AUTOSAR XML (schema 3.1.2)
package /Components/SWC_AdvOptmT
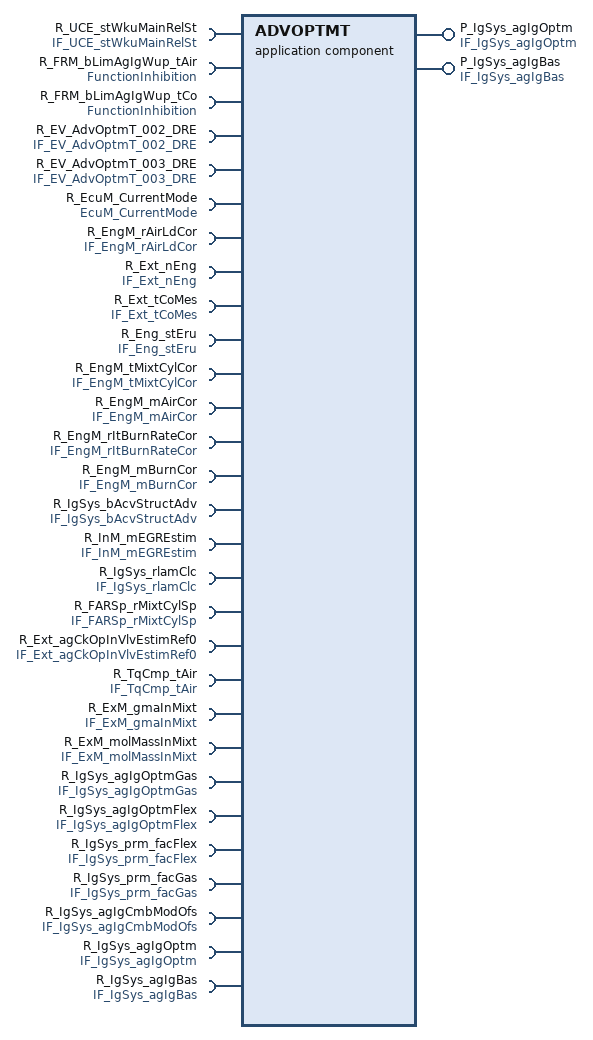
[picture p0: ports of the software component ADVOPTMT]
  application software component type ADVOPTMT  # AdvOptmT
    require port R_UCE_stWkuMainRelSt: required-interface=IF_UCE_stWkuMainRelSt
    require port R_FRM_bLimAgIgWup_tAir: required-interface=FunctionInhibition
    require port R_FRM_bLimAgIgWup_tCo: required-interface=FunctionInhibition
    provide port P_IgSys_agIgOptm: unqueued-sender-com-spec{data-element=IgSys_agIgOptm, can-invalidate=false, init-value=ConstantValue}, provided-interface=IF_IgSys_agIgOptm
    provide port P_IgSys_agIgBas: unqueued-sender-com-spec{data-element=IgSys_agIgBas, can-invalidate=false, init-value=UInt8InitValue}, provided-interface=IF_IgSys_agIgBas
    26 x require port:
      R_EV_AdvOptmT_002_DRE: unqueued-receiver-com-spec{data-element=EV_AdvOptmT_002_DRE, init-value=UInt8InitValue1, resync-time=0}, required-interface=IF_EV_AdvOptmT_002_DRE
      R_EV_AdvOptmT_003_DRE: unqueued-receiver-com-spec{data-element=EV_AdvOptmT_003_DRE, init-value=UInt8InitValue3, resync-time=0}, required-interface=IF_EV_AdvOptmT_003_DRE
      R_EcuM_CurrentMode: required-interface=EcuM_CurrentMode
      R_EngM_rAirLdCor: unqueued-receiver-com-spec{data-element=EngM_rAirLdCor, init-value=ConstantValue5, resync-time=0}, required-interface=IF_EngM_rAirLdCor
      R_Ext_nEng: unqueued-receiver-com-spec{data-element=Ext_nEng, init-value=ConstantValue7, resync-time=0}, required-interface=IF_Ext_nEng
      R_Ext_tCoMes: unqueued-receiver-com-spec{data-element=Ext_tCoMes, init-value=ConstantValue9, resync-time=0}, required-interface=IF_Ext_tCoMes
      R_Eng_stEru: unqueued-receiver-com-spec{data-element=Eng_stEru, init-value=ConstantValue11, resync-time=0}, required-interface=IF_Eng_stEru
      R_EngM_tMixtCylCor: unqueued-receiver-com-spec{data-element=EngM_tMixtCylCor, init-value=UInt16InitValue, resync-time=0}, required-interface=IF_EngM_tMixtCylCor
      R_EngM_mAirCor: unqueued-receiver-com-spec{data-element=EngM_mAirCor, init-value=UInt16InitValue13, resync-time=0}, required-interface=IF_EngM_mAirCor
      R_EngM_rItBurnRateCor: unqueued-receiver-com-spec{data-element=EngM_rItBurnRateCor, init-value=UInt16InitValue15, resync-time=0}, required-interface=IF_EngM_rItBurnRateCor
      R_EngM_mBurnCor: unqueued-receiver-com-spec{data-element=EngM_mBurnCor, init-value=UInt16InitValue17, resync-time=0}, required-interface=IF_EngM_mBurnCor
      R_IgSys_bAcvStructAdv: unqueued-receiver-com-spec{data-element=IgSys_bAcvStructAdv, init-value=ConstantValue19, resync-time=0}, required-interface=IF_IgSys_bAcvStructAdv
      R_InM_mEGREstim: unqueued-receiver-com-spec{data-element=InM_mEGREstim, init-value=UInt32InitValue, resync-time=0}, required-interface=IF_InM_mEGREstim
      R_IgSys_rlamClc: unqueued-receiver-com-spec{data-element=IgSys_rlamClc, init-value=UInt16InitValue21, resync-time=0}, required-interface=IF_IgSys_rlamClc
      R_FARSp_rMixtCylSp: unqueued-receiver-com-spec{data-element=FARSp_rMixtCylSp, init-value=ConstantValue23, resync-time=0}, required-interface=IF_FARSp_rMixtCylSp
      R_Ext_agCkOpInVlvEstimRef0: unqueued-receiver-com-spec{data-element=Ext_agCkOpInVlvEstimRef0, init-value=ConstantValue25, resync-time=0}, required-interface=IF_Ext_agCkOpInVlvEstimRef0
      R_TqCmp_tAir: unqueued-receiver-com-spec{data-element=TqCmp_tAir, init-value=SInt8InitValue, resync-time=0}, required-interface=IF_TqCmp_tAir
      R_ExM_gmaInMixt: unqueued-receiver-com-spec{data-element=ExM_gmaInMixt, init-value=UInt16InitValue27, resync-time=0}, required-interface=IF_ExM_gmaInMixt
      R_ExM_molMassInMixt: unqueued-receiver-com-spec{data-element=ExM_molMassInMixt, init-value=UInt16InitValue29, resync-time=0}, required-interface=IF_ExM_molMassInMixt
      R_IgSys_agIgOptmGas: unqueued-receiver-com-spec{data-element=IgSys_agIgOptmGas, init-value=UInt8InitValue31, resync-time=0}, required-interface=IF_IgSys_agIgOptmGas
      R_IgSys_agIgOptmFlex: unqueued-receiver-com-spec{data-element=IgSys_agIgOptmFlex, init-value=UInt8InitValue33, resync-time=0}, required-interface=IF_IgSys_agIgOptmFlex
      R_IgSys_prm_facFlex: unqueued-receiver-com-spec{data-element=IgSys_prm_facFlex, init-value=ArrayConstantValue, resync-time=0}, required-interface=IF_IgSys_prm_facFlex
      R_IgSys_prm_facGas: unqueued-receiver-com-spec{data-element=IgSys_prm_facGas, init-value=ArrayConstantValue35, resync-time=0}, required-interface=IF_IgSys_prm_facGas
      R_IgSys_agIgCmbModOfs: unqueued-receiver-com-spec{data-element=IgSys_agIgCmbModOfs, init-value=UInt8InitValue37, resync-time=0}, required-interface=IF_IgSys_agIgCmbModOfs
      R_IgSys_agIgOptm: unqueued-receiver-com-spec{data-element=IgSys_agIgOptm, init-value=ConstantValue, resync-time=0}, required-interface=IF_IgSys_agIgOptm
      R_IgSys_agIgBas: unqueued-receiver-com-spec{data-element=IgSys_agIgBas, init-value=UInt8InitValue, resync-time=0}, required-interface=IF_IgSys_agIgBas
  27 x constant specification:
    ArrayConstantValue
      value:
        array specification ArrayConstantValue: type=rt_Array_UInt8_10_m0
          10 x integer literal, all with type=DT_IgSys_prm_facFlex, value=0:
            Const
            Const{1..9}
    ArrayConstantValue35
      value:
        array specification ArrayConstantValue35: type=rt_Array_UInt8_10_m1
          10 x integer literal, all with type=DT_IgSys_prm_facGas, value=0:
            Const
            Const{1..9}
    ConstantValue
      value:
        integer literal ConstantValue: type=DT_IgSys_agIgOptm, value=149
    ConstantValue11
      value:
        integer literal ConstantValue11: type=DT_Eng_stEru, value=1
    ConstantValue19
      value:
        boolean literal ConstantValue19: type=DT_IgSys_bAcvStructAdv, value=false
    ConstantValue23
      value:
        integer literal ConstantValue23: type=DT_FARSp_rMixtCylSp, value=4096
    ConstantValue25
      value:
        integer literal ConstantValue25: type=DT_Ext_agCkOpInVlvEstimRef0, value=-1024
    ConstantValue5
      value:
        integer literal ConstantValue5: type=DT_EngM_rAirLdCor, value=0
    ConstantValue7
      value:
        integer literal ConstantValue7: type=DT_Ext_nEng, value=0
    ConstantValue9
      value:
        integer literal ConstantValue9: type=DT_Ext_tCoMes, value=20
    InitValue_Boolean_0
      value:
        boolean literal InitValue_Boolean_0: type=DT_IgSys_bAcvClsLoop_irv, value=false
    InitValue_Float32_0
      value:
        real literal InitValue_Float32_0: type=DT_IgSys_agIgWup_irv, value=0
    SInt8InitValue
      value:
        integer literal SInt8InitValue: type=DT_TqCmp_tAir, value=-40
    UInt16InitValue
      value:
        integer literal UInt16InitValue: type=DT_EngM_tMixtCylCor, value=0
    UInt16InitValue13
      value:
        integer literal UInt16InitValue13: type=DT_EngM_mAirCor, value=0
    UInt16InitValue15
      value:
        integer literal UInt16InitValue15: type=DT_EngM_rItBurnRateCor, value=0
    UInt16InitValue17
      value:
        integer literal UInt16InitValue17: type=DT_EngM_mBurnCor, value=0
    UInt16InitValue21
      value:
        integer literal UInt16InitValue21: type=DT_IgSys_rlamClc, value=1
    UInt16InitValue27
      value:
        integer literal UInt16InitValue27: type=DT_ExM_gmaInMixt, value=0
    UInt16InitValue29
      value:
        integer literal UInt16InitValue29: type=DT_ExM_molMassInMixt, value=0
    UInt32InitValue
      value:
        integer literal UInt32InitValue: type=DT_InM_mEGREstim, value=0
    UInt8InitValue
      value:
        integer literal UInt8InitValue: type=DT_IgSys_agIgBas, value=149
    UInt8InitValue1
      value:
        integer literal UInt8InitValue1: type=DT_EV_AdvOptmT_002_DRE, value=0
    UInt8InitValue3
      value:
        integer literal UInt8InitValue3: type=DT_EV_AdvOptmT_003_DRE, value=0
    UInt8InitValue31
      value:
        integer literal UInt8InitValue31: type=DT_IgSys_agIgOptmGas, value=96
    UInt8InitValue33
      value:
        integer literal UInt8InitValue33: type=DT_IgSys_agIgOptmFlex, value=96
    UInt8InitValue37
      value:
        integer literal UInt8InitValue37: type=DT_IgSys_agIgCmbModOfs, value=96
  internal behavior IB_AdvOptmT: component=ADVOPTMT
    data received event EV_AdvOptmT_003_DRE: mode-dependency=dependent-on-mode=[R_UCE_stWkuMainRelSt.RCD_stWkuMainRelSt.PreMainWakeUp, R_UCE_stWkuMainRelSt.RCD_stWkuMainRelSt.PostMainWakeUp, R_UCE_stWkuMainRelSt.RCD_stWkuMainRelSt.Invalid], start-on-event=RE_AdvOptmT_003_DRE, data=R_EV_AdvOptmT_003_DRE.EV_AdvOptmT_003_DRE
    mode switch event EV_AdvOptmT_004_MSE: start-on-event=RE_AdvOptmT_004_MSE, activation=ENTRY, mode=R_EcuM_CurrentMode.currentMode.RUN
    mode switch event EV_AdvOptmT_001_MSE: start-on-event=RE_AdvOptmT_001_MSE, activation=ENTRY, mode=R_EcuM_CurrentMode.currentMode.RUN
    data received event EV_AdvOptmT_002_DRE: mode-dependency=dependent-on-mode=[R_UCE_stWkuMainRelSt.RCD_stWkuMainRelSt.PreMainWakeUp, R_UCE_stWkuMainRelSt.RCD_stWkuMainRelSt.PostMainWakeUp, R_UCE_stWkuMainRelSt.RCD_stWkuMainRelSt.Invalid], start-on-event=RE_AdvOptmT_002_DRE, data=R_EV_AdvOptmT_002_DRE.EV_AdvOptmT_002_DRE
    inter runnable variable IgSys_bAcvClsLoop_irv: sw-calibration-access=READ-WRITE, type=DT_IgSys_bAcvClsLoop_irv, communication-approach=EXPLICIT, init-value=InitValue_Boolean_0
    inter runnable variable IgSys_agIgWup_irv: sw-calibration-access=READ-WRITE, type=DT_IgSys_agIgWup_irv, communication-approach=EXPLICIT, init-value=InitValue_Float32_0
    4 x runnable:
      RE_AdvOptmT_001_MSE: written-variable=IgSys_agIgWup_irv
      RE_AdvOptmT_002_DRE: read-variable=IgSys_agIgWup_irv, written-variable=IgSys_agIgWup_irv
        7 x data receive point:
          dr_EngM_rAirLdCor: data-element=R_EngM_rAirLdCor.EngM_rAirLdCor
          dr_Ext_nEng: data-element=R_Ext_nEng.Ext_nEng
          dr_Eng_stEru: data-element=R_Eng_stEru.Eng_stEru
          dr_TqCmp_tAir: data-element=R_TqCmp_tAir.TqCmp_tAir
          dr_EV_AdvOptmT_002_DRE: data-element=R_EV_AdvOptmT_002_DRE.EV_AdvOptmT_002_DRE
          dr_Ext_tCoMes: data-element=R_Ext_tCoMes.Ext_tCoMes
          dr_IgSys_bAcvStructAdv: data-element=R_IgSys_bAcvStructAdv.IgSys_bAcvStructAdv
        sync call ssp_FRM_bLimAgIgWup_tCo: operation=R_FRM_bLimAgIgWup_tCo.GetFunctionPermission
        sync call ssp_FRM_bLimAgIgWup_tAir: operation=R_FRM_bLimAgIgWup_tAir.GetFunctionPermission
      RE_AdvOptmT_003_DRE: read-variable=[IgSys_bAcvClsLoop_irv, IgSys_agIgWup_irv], written-variable=IgSys_bAcvClsLoop_irv
        22 x data receive point:
          dr_IgSys_agIgBas: data-element=R_IgSys_agIgBas.IgSys_agIgBas
          DRP_R_IgSys_agIgOptm_IgSys_agIgOptm: data-element=R_IgSys_agIgOptm.IgSys_agIgOptm
          dr_Eng_stEru: data-element=R_Eng_stEru.Eng_stEru
          dr_IgSys_prm_facGas: data-element=R_IgSys_prm_facGas.IgSys_prm_facGas
          dr_EngM_mBurnCor: data-element=R_EngM_mBurnCor.EngM_mBurnCor
          dr_IgSys_agIgOptmFlex: data-element=R_IgSys_agIgOptmFlex.IgSys_agIgOptmFlex
          dr_EngM_mAirCor: data-element=R_EngM_mAirCor.EngM_mAirCor
          dr_IgSys_prm_facFlex: data-element=R_IgSys_prm_facFlex.IgSys_prm_facFlex
          dr_Ext_agCkOpInVlvEstimRef0: data-element=R_Ext_agCkOpInVlvEstimRef0.Ext_agCkOpInVlvEstimRef0
          dr_EngM_rItBurnRateCor: data-element=R_EngM_rItBurnRateCor.EngM_rItBurnRateCor
          dr_EV_AdvOptmT_003_DRE: data-element=R_EV_AdvOptmT_003_DRE.EV_AdvOptmT_003_DRE
          dr_IgSys_agIgCmbModOfs: data-element=R_IgSys_agIgCmbModOfs.IgSys_agIgCmbModOfs
          dr_ExM_molMassInMixt: data-element=R_ExM_molMassInMixt.ExM_molMassInMixt
          dr_InM_mEGREstim: data-element=R_InM_mEGREstim.InM_mEGREstim
          dr_FARSp_rMixtCylSp: data-element=R_FARSp_rMixtCylSp.FARSp_rMixtCylSp
          dr_IgSys_agIgOptmGas: data-element=R_IgSys_agIgOptmGas.IgSys_agIgOptmGas
          dr_EngM_rAirLdCor: data-element=R_EngM_rAirLdCor.EngM_rAirLdCor
          dr_ExM_gmaInMixt: data-element=R_ExM_gmaInMixt.ExM_gmaInMixt
          dr_Ext_tCoMes: data-element=R_Ext_tCoMes.Ext_tCoMes
          dr_Ext_nEng: data-element=R_Ext_nEng.Ext_nEng
          dr_EngM_tMixtCylCor: data-element=R_EngM_tMixtCylCor.EngM_tMixtCylCor
          dr_IgSys_rlamClc: data-element=R_IgSys_rlamClc.IgSys_rlamClc
        data send point ds_IgSys_agIgBas: data-element=P_IgSys_agIgBas.IgSys_agIgBas
        data send point ds_IgSys_agIgOptm: data-element=P_IgSys_agIgOptm.IgSys_agIgOptm
      RE_AdvOptmT_004_MSE: written-variable=IgSys_bAcvClsLoop_irv
        data send point ds_IgSys_agIgBas: data-element=P_IgSys_agIgBas.IgSys_agIgBas
        data send point ds_IgSys_agIgOptm: data-element=P_IgSys_agIgOptm.IgSys_agIgOptm
  swc implementation Imp_AdvOptmT: code-generator=Real-Time Workshop Embedded Coder 5.5 (R2010a) 25-Jan-2010, programming-language=C, behavior=IB_AdvOptmT
    code-descriptors:
      code CodeDescriptor: type=SRC
        9 x xfile:
          AdvOptmT_h: url=AdvOptmT.h
          AdvOptmT_Version_h: url=AdvOptmT_Version.h
          AdvOptmT_Version_c: url=AdvOptmT_Version.c
          AdvOptmT_private_h: url=AdvOptmT_private.h
          AdvOptmT_c: url=AdvOptmT.c
          AdvOptmT_MemMap_h: url=AdvOptmT_MemMap.h
          AdvOptmT_import_h: url=AdvOptmT_import.h
          AdvOptmT_Def_c: url=AdvOptmT_Def.c
          AdvOptmT_types_h: url=AdvOptmT_types.h
package /Components/SWC_AdvOptmT/AdvOptmT_IRVDatatypes
  boolean type DT_IgSys_bAcvClsLoop_irv: base-type=boolean
  real type DT_IgSys_agIgWup_irv: base-type=float32, allow-nan=false, encoding=SINGLE
